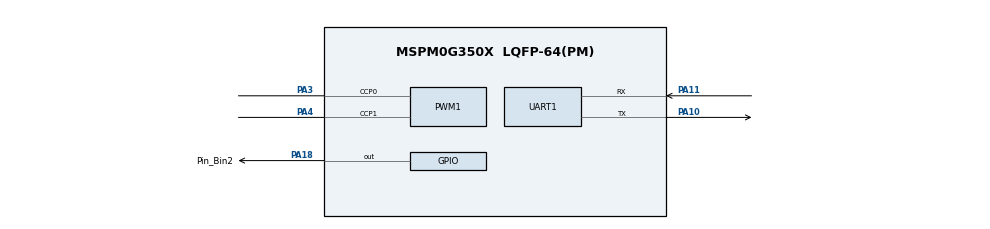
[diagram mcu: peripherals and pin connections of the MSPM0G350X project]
/**
 * These arguments were used when this file was generated. They will be automatically applied on subsequent loads
 * via the GUI or CLI. Run CLI with '--help' for additional information on how to override these arguments.
 * @cliArgs --device "MSPM0G350X" --package "LQFP-64(PM)" --part "Default" --product "mspm0_sdk@2.01.00.03"
 * @versions {"tool":"1.20.0+3587"}
 */

/**
 * Import the modules used in this configuration.
 */
const GPIO    = scripting.addModule("/ti/driverlib/GPIO", {}, false);
const GPIO1   = GPIO.addInstance();
const GPIO2   = GPIO.addInstance();
const GPIO3   = GPIO.addInstance();
const GPIO4   = GPIO.addInstance();
const GPIO5   = GPIO.addInstance();
const GPIO6   = GPIO.addInstance();
const GPIO7   = GPIO.addInstance();
const GPIO8   = GPIO.addInstance();
const GPIO9   = GPIO.addInstance();
const GPIO10  = GPIO.addInstance();
const GPIO11  = GPIO.addInstance();
const GPIO12  = GPIO.addInstance();
const GPIO13  = GPIO.addInstance();
const PWM     = scripting.addModule("/ti/driverlib/PWM", {}, false);
const PWM1    = PWM.addInstance();
const SYSCTL  = scripting.addModule("/ti/driverlib/SYSCTL");
const SYSTICK = scripting.addModule("/ti/driverlib/SYSTICK");
const TIMER   = scripting.addModule("/ti/driverlib/TIMER", {}, false);
const TIMER1  = TIMER.addInstance();
const UART    = scripting.addModule("/ti/driverlib/UART", {}, false);
const UART1   = UART.addInstance();

/**
 * Write custom configuration values to the imported modules.
 */
GPIO1.$name                              = "LED1";
GPIO1.port                               = "PORTA";
GPIO1.associatedPins[0].$name            = "PIN_0";
GPIO1.associatedPins[0].internalResistor = "PULL_DOWN";
GPIO1.associatedPins[0].assignedPin      = "0";

const Board = scripting.addModule("/ti/driverlib/Board", {}, false);

GPIO2.$name                              = "KEY0";
GPIO2.port                               = "PORTB";
GPIO2.associatedPins[0].direction        = "INPUT";
GPIO2.associatedPins[0].polarity         = "RISE";
GPIO2.associatedPins[0].$name            = "PIN_18";
GPIO2.associatedPins[0].internalResistor = "PULL_UP";
GPIO2.associatedPins[0].assignedPin      = "9";

GPIO3.$name                               = "ENCODERA";
GPIO3.port                                = "PORTA";
GPIO3.associatedPins.create(2);
GPIO3.associatedPins[0].direction         = "INPUT";
GPIO3.associatedPins[0].interruptEn       = true;
GPIO3.associatedPins[0].polarity          = "RISE";
GPIO3.associatedPins[0].interruptPriority = "0";
GPIO3.associatedPins[0].$name             = "E1A";
GPIO3.associatedPins[0].assignedPin       = "15";
GPIO3.associatedPins[1].direction         = "INPUT";
GPIO3.associatedPins[1].interruptEn       = true;
GPIO3.associatedPins[1].polarity          = "RISE";
GPIO3.associatedPins[1].interruptPriority = "0";
GPIO3.associatedPins[1].$name             = "E1B";
GPIO3.associatedPins[1].assignedPin       = "16";

GPIO4.$name                         = "RGB_Red";
GPIO4.port                          = "PORTB";
GPIO4.associatedPins[0].$name       = "PIN_26";
GPIO4.associatedPins[0].assignedPin = "26";

GPIO5.$name                         = "AIN1";
GPIO5.port                          = "PORTA";
GPIO5.associatedPins[0].$name       = "PIN_12";
GPIO5.associatedPins[0].assignedPin = "12";

GPIO6.$name                         = "AIN2";
GPIO6.port                          = "PORTA";
GPIO6.associatedPins[0].$name       = "PIN_13";
GPIO6.associatedPins[0].assignedPin = "13";

GPIO7.$name                                       = "BIN1";
GPIO7.port                                        = "PORTA";
GPIO7.associatedPins[0].$name                     = "Pin_Bin1";
GPIO7.associatedPins[0].assignedPin               = "14";
GPIO7.associatedPins[0].pin.$assignAllowConflicts = "PA14";

GPIO8.$name                         = "BIN2";
GPIO8.port                          = "PORTA";
GPIO8.associatedPins[0].$name       = "Pin_Bin2";
GPIO8.associatedPins[0].assignedPin = "18";
GPIO8.associatedPins[0].pin.$assign = "PA18";

GPIO9.$name                               = "ENCODERB";
GPIO9.port                                = "PORTA";
GPIO9.associatedPins.create(2);
GPIO9.associatedPins[0].$name             = "E2A";
GPIO9.associatedPins[0].direction         = "INPUT";
GPIO9.associatedPins[0].assignedPin       = "17";
GPIO9.associatedPins[0].interruptEn       = true;
GPIO9.associatedPins[0].polarity          = "RISE";
GPIO9.associatedPins[0].interruptPriority = "0";
GPIO9.associatedPins[1].$name             = "E2B";
GPIO9.associatedPins[1].direction         = "INPUT";
GPIO9.associatedPins[1].assignedPin       = "22";
GPIO9.associatedPins[1].interruptEn       = true;
GPIO9.associatedPins[1].polarity          = "RISE";
GPIO9.associatedPins[1].interruptPriority = "0";

GPIO10.$name                              = "KEY3";
GPIO10.port                               = "PORTB";
GPIO10.associatedPins[0].$name            = "PIN_22";
GPIO10.associatedPins[0].direction        = "INPUT";
GPIO10.associatedPins[0].internalResistor = "PULL_UP";
GPIO10.associatedPins[0].assignedPin      = "8";

GPIO11.$name                              = "KEY2";
GPIO11.port                               = "PORTB";
GPIO11.associatedPins[0].$name            = "PIN_19";
GPIO11.associatedPins[0].direction        = "INPUT";
GPIO11.associatedPins[0].internalResistor = "PULL_UP";
GPIO11.associatedPins[0].assignedPin      = "7";

GPIO12.$name                         = "KEY1";
GPIO12.port                          = "PORTB";
GPIO12.associatedPins[0].$name       = "PIN_1";
GPIO12.associatedPins[0].direction   = "INPUT";
GPIO12.associatedPins[0].assignedPin = "6";

GPIO13.$name                         = "BUZZER";
GPIO13.port                          = "PORTA";
GPIO13.associatedPins[0].$name       = "PIN_2";
GPIO13.associatedPins[0].assignedPin = "1";

PWM1.$name                      = "PWM_0";
PWM1.clockDivider               = 8;
PWM1.timerCount                 = 10000;
PWM1.timerStartTimer            = true;
PWM1.peripheral.$assign         = "TIMG7";
PWM1.peripheral.ccp0Pin.$assign = "PA3";
PWM1.peripheral.ccp1Pin.$assign = "PA4";
PWM1.PWM_CHANNEL_0.$name        = "ti_driverlib_pwm_PWMTimerCC0";
PWM1.PWM_CHANNEL_0.dutyCycle    = 80;
PWM1.PWM_CHANNEL_1.$name        = "ti_driverlib_pwm_PWMTimerCC1";
PWM1.PWM_CHANNEL_1.dutyCycle    = 50;
PWM1.ccp0PinConfig.$name        = "ti_driverlib_gpio_GPIOPinGeneric2";
PWM1.ccp1PinConfig.$name        = "ti_driverlib_gpio_GPIOPinGeneric3";

SYSCTL.forceDefaultClkConfig = true;
SYSCTL.clockTreeEn           = true;

SYSTICK.periodEnable      = true;
SYSTICK.systickEnable     = true;
SYSTICK.interruptPriority = "0";
SYSTICK.period            = 32;

TIMER1.$name             = "TIMER_0";
TIMER1.timerClkDiv       = 8;
TIMER1.timerClkPrescale  = 200;
TIMER1.timerPeriod       = "5 ms";
TIMER1.timerStartTimer   = true;
TIMER1.timerMode         = "PERIODIC";
TIMER1.interrupts        = ["ZERO"];
TIMER1.interruptPriority = "3";

UART1.$name                    = "UART_0";
UART1.enabledInterrupts        = ["RX"];
UART1.targetBaudRate           = 230400;
UART1.interruptPriority        = "1";
UART1.peripheral.$assign       = "UART0";
UART1.peripheral.rxPin.$assign = "PA11";
UART1.peripheral.txPin.$assign = "PA10";
UART1.txPinConfig.$name        = "ti_driverlib_gpio_GPIOPinGeneric0";
UART1.rxPinConfig.$name        = "ti_driverlib_gpio_GPIOPinGeneric1";

/**
 * Pinmux solution for unlocked pins/peripherals. This ensures that minor changes to the automatic solver in a future
 * version of the tool will not impact the pinmux you originally saw.  These lines can be completely deleted in order to
 * re-solve from scratch.
 */
GPIO1.associatedPins[0].pin.$suggestSolution  = "PA0";
Board.peripheral.$suggestSolution             = "DEBUGSS";
Board.peripheral.swclkPin.$suggestSolution    = "PA20";
Board.peripheral.swdioPin.$suggestSolution    = "PA19";
GPIO2.associatedPins[0].pin.$suggestSolution  = "PB9";
GPIO3.associatedPins[0].pin.$suggestSolution  = "PA15";
GPIO3.associatedPins[1].pin.$suggestSolution  = "PA16";
GPIO4.associatedPins[0].pin.$suggestSolution  = "PB26";
GPIO5.associatedPins[0].pin.$suggestSolution  = "PA12";
GPIO6.associatedPins[0].pin.$suggestSolution  = "PA13";
GPIO9.associatedPins[0].pin.$suggestSolution  = "PA17";
GPIO9.associatedPins[1].pin.$suggestSolution  = "PA22";
GPIO10.associatedPins[0].pin.$suggestSolution = "PB8";
GPIO11.associatedPins[0].pin.$suggestSolution = "PB7";
GPIO12.associatedPins[0].pin.$suggestSolution = "PB6";
GPIO13.associatedPins[0].pin.$suggestSolution = "PA1";
TIMER1.peripheral.$suggestSolution            = "TIMA0";
